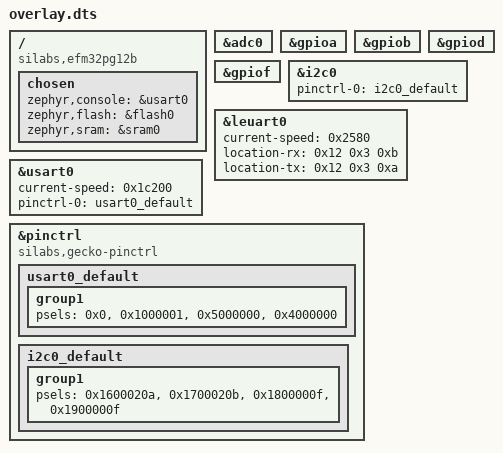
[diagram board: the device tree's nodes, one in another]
/ {
	compatible = "silabs,efm32pg12b", "silabs,efm32pg_stk3402a";
	chosen {
		zephyr,console = &usart0;
		zephyr,flash = &flash0;
		zephyr,sram = &sram0;
	};
};
&adc0{
	status = "okay";
};
&gpioa{
	status = "okay";
};
&gpiob{
	status = "okay";
};
&gpiod{
	status = "okay";
};
&gpiof{
	status = "okay";
};
&i2c0{
	status = "okay";
	pinctrl-0 = < &i2c0_default >;
	pinctrl-names = "default";
};
&leuart0{
	status = "okay";
	current-speed = < 0x2580 >;
	location-rx = < 0x12 0x3 0xb >;
	location-tx = < 0x12 0x3 0xa >;
};
&usart0{
	status = "okay";
	current-speed = < 0x1c200 >;
	pinctrl-0 = < &usart0_default >;
	pinctrl-names = "default";
};
&pinctrl{
	compatible = "silabs,gecko-pinctrl";
	usart0_default: usart0_default {
		group1 {
			psels = < 0x0 >, < 0x1000001 >, < 0x5000000 >, < 0x4000000 >;
		};
	};
	i2c0_default: i2c0_default {
		group1 {
			psels = < 0x1600020a >, < 0x1700020b >, < 0x1800000f >, < 0x1900000f >;
		};
	};
};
